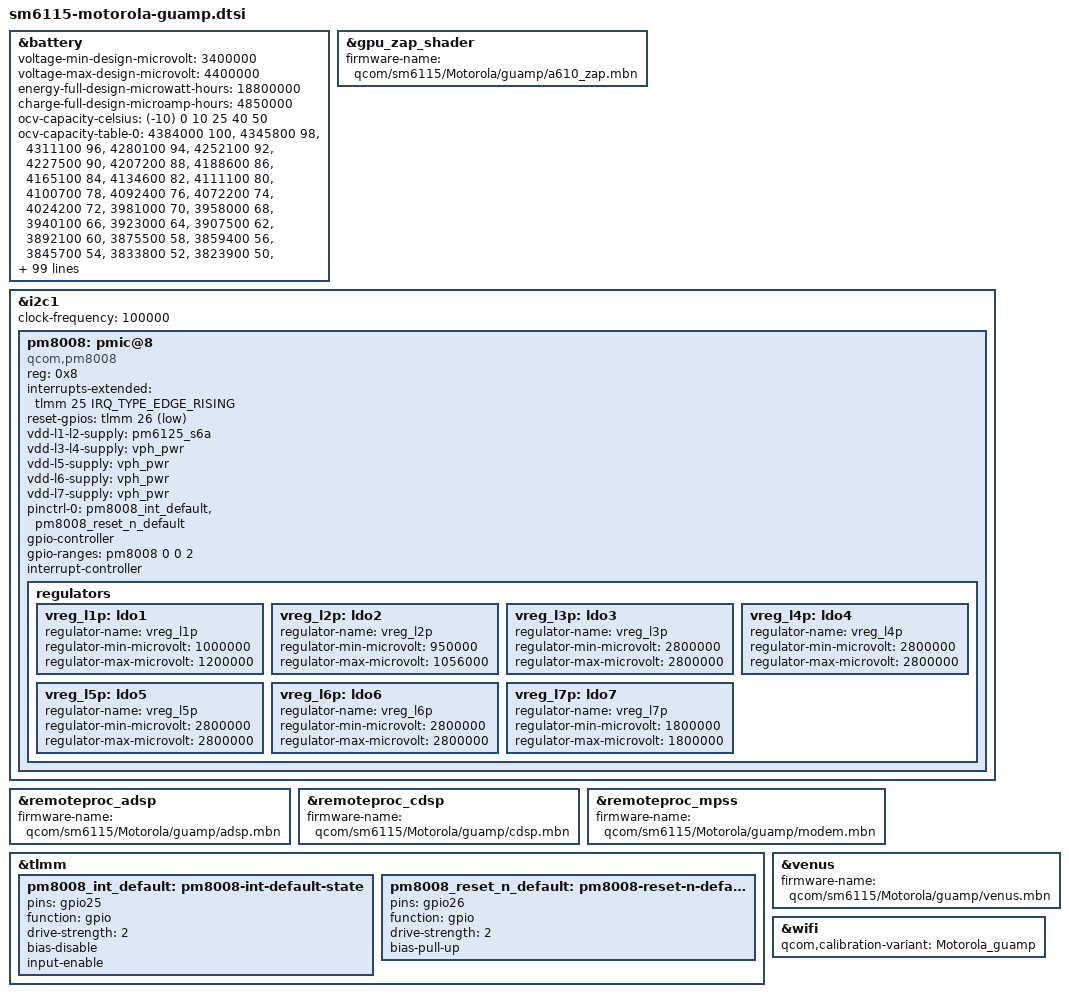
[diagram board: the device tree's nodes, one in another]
// SPDX-License-Identifier: (GPL-2.0+ OR BSD-3-Clause)
/*
 * Copyright (c) 2026, Val Packett <val@packett.cool>
 */

#include "sm6115.dtsi"
#include "sm6115-motorola-common.dtsi"

&battery {
	voltage-min-design-microvolt = <3400000>;
	voltage-max-design-microvolt = <4400000>;
	energy-full-design-microwatt-hours = <18800000>;
	charge-full-design-microamp-hours = <4850000>;

	ocv-capacity-celsius = <(-10) 0 10 25 40 50>;

	ocv-capacity-table-0 =
		<4384000 100>, <4345800 98>, <4311100 96>, <4280100 94>,
		<4252100 92>, <4227500 90>, <4207200 88>, <4188600 86>,
		<4165100 84>, <4134600 82>, <4111100 80>, <4100700 78>,
		<4092400 76>, <4072200 74>, <4024200 72>, <3981000 70>,
		<3958000 68>, <3940100 66>, <3923000 64>, <3907500 62>,
		<3892100 60>, <3875500 58>, <3859400 56>, <3845700 54>,
		<3833800 52>, <3823900 50>, <3816000 48>, <3809300 46>,
		<3803000 44>, <3797100 42>, <3791500 40>, <3786000 38>,
		<3780800 36>, <3775100 34>, <3769400 32>, <3763400 30>,
		<3757100 28>, <3750600 26>, <3744100 24>, <3737600 22>,
		<3731100 20>, <3724800 18>, <3718300 16>, <3711600 14>,
		<3703900 12>, <3693500 10>, <3688000 9>, <3680900 8>,
		<3672100 7>, <3657600 6>, <3633000 5>, <3592200 4>,
		<3532000 3>, <3443800 2>, <3305600 1>;

	ocv-capacity-table-1 =
		<4382000 100>, <4347400 98>, <4315800 96>, <4287600 94>,
		<4262600 92>, <4238400 90>, <4214200 88>, <4190500 86>,
		<4166800 84>, <4142900 82>, <4120900 80>, <4102900 78>,
		<4085800 76>, <4064800 74>, <4039300 72>, <4012900 70>,
		<3985900 68>, <3959900 66>, <3939900 64>, <3924200 62>,
		<3909200 60>, <3893000 58>, <3877200 56>, <3862900 54>,
		<3850200 52>, <3837800 50>, <3824400 48>, <3812000 46>,
		<3803700 44>, <3797800 42>, <3792900 40>, <3789000 38>,
		<3785400 36>, <3781200 34>, <3776500 32>, <3771500 30>,
		<3766800 28>, <3761800 26>, <3755600 24>, <3748300 22>,
		<3740000 20>, <3730300 18>, <3719300 16>, <3707500 14>,
		<3697100 12>, <3687900 10>, <3683900 9>, <3679500 8>,
		<3673600 7>, <3664100 6>, <3643300 5>, <3601900 4>,
		<3541600 3>, <3455500 2>, <3320700 1>;

	ocv-capacity-table-2 =
		<4381000 100>, <4351700 98>, <4323800 96>, <4297400 94>,
		<4272400 92>, <4248100 90>, <4224100 88>, <4200600 86>,
		<4177800 84>, <4155600 82>, <4134000 80>, <4113300 78>,
		<4093000 76>, <4072300 74>, <4051300 72>, <4029700 70>,
		<4006300 68>, <3982700 66>, <3961100 64>, <3940800 62>,
		<3921900 60>, <3903600 58>, <3886900 56>, <3872000 54>,
		<3858800 52>, <3846700 50>, <3835800 48>, <3825700 46>,
		<3816500 44>, <3807900 42>, <3800100 40>, <3792600 38>,
		<3786000 36>, <3781000 34>, <3777100 32>, <3773100 30>,
		<3769300 28>, <3765100 26>, <3759600 24>, <3752800 22>,
		<3744800 20>, <3735000 18>, <3723400 16>, <3709000 14>,
		<3696800 12>, <3688900 10>, <3686300 9>, <3684000 8>,
		<3679900 7>, <3671800 6>, <3647900 5>, <3599800 4>,
		<3535000 3>, <3447700 2>, <3319500 1>;

	ocv-capacity-table-3 =
		<4374500 100>, <4344200 98>, <4315800 96>, <4289700 94>,
		<4265800 92>, <4242300 90>, <4218800 88>, <4195500 86>,
		<4172600 84>, <4150000 82>, <4128000 80>, <4106800 78>,
		<4086100 76>, <4065600 74>, <4044900 72>, <4024900 70>,
		<4005700 68>, <3987300 66>, <3970300 64>, <3955200 62>,
		<3938400 60>, <3915500 58>, <3891200 56>, <3873300 54>,
		<3859400 52>, <3847400 50>, <3836700 48>, <3827300 46>,
		<3818500 44>, <3810400 42>, <3803100 40>, <3796300 38>,
		<3790200 36>, <3784300 34>, <3779000 32>, <3773600 30>,
		<3767800 28>, <3761700 26>, <3755000 24>, <3747800 22>,
		<3739700 20>, <3730000 18>, <3718700 16>, <3704800 14>,
		<3693100 12>, <3687700 10>, <3686000 9>, <3684000 8>,
		<3681100 7>, <3674000 6>, <3648000 5>, <3600400 4>,
		<3537900 3>, <3454700 2>, <3329300 1>;

	ocv-capacity-table-4 =
		<4372500 100>, <4344800 98>, <4318300 96>, <4293100 94>,
		<4269200 92>, <4245700 90>, <4222200 88>, <4199000 86>,
		<4176100 84>, <4153400 82>, <4131100 80>, <4109100 78>,
		<4087600 76>, <4067100 74>, <4047200 72>, <4027900 70>,
		<4009000 68>, <3990900 66>, <3974200 64>, <3959000 62>,
		<3941900 60>, <3919100 58>, <3895300 56>, <3877300 54>,
		<3862400 52>, <3849700 50>, <3838800 48>, <3829200 46>,
		<3820400 44>, <3812500 42>, <3805300 40>, <3798800 38>,
		<3792700 36>, <3786200 34>, <3779500 32>, <3772000 30>,
		<3763300 28>, <3754300 26>, <3746200 24>, <3738700 22>,
		<3730700 20>, <3721600 18>, <3710900 16>, <3697100 14>,
		<3686400 12>, <3682000 10>, <3680600 9>, <3679300 8>,
		<3676600 7>, <3667800 6>, <3637400 5>, <3588100 4>,
		<3523900 3>, <3435900 2>, <3308000 1>;

	ocv-capacity-table-5 =
		<4371500 100>, <4344300 98>, <4318200 96>, <4293400 94>,
		<4269700 92>, <4246400 90>, <4222900 88>, <4199600 86>,
		<4176600 84>, <4153900 82>, <4131600 80>, <4109800 78>,
		<4088300 76>, <4067700 74>, <4047400 72>, <4028100 70>,
		<4009600 68>, <3991900 66>, <3975200 64>, <3959600 62>,
		<3942200 60>, <3919500 58>, <3896000 56>, <3878100 54>,
		<3863200 52>, <3850400 50>, <3839300 48>, <3829500 46>,
		<3820500 44>, <3812400 42>, <3805100 40>, <3798300 38>,
		<3791900 36>, <3785100 34>, <3778000 32>, <3769800 30>,
		<3759500 28>, <3748700 26>, <3740000 24>, <3732400 22>,
		<3724300 20>, <3715400 18>, <3704800 16>, <3690800 14>,
		<3680400 12>, <3676300 10>, <3675300 9>, <3674100 8>,
		<3670900 7>, <3660200 6>, <3627200 5>, <3577200 4>,
		<3512300 3>, <3423400 2>, <3292200 1>;
};

&gpu_zap_shader {
	firmware-name = "qcom/sm6115/Motorola/guamp/a610_zap.mbn";
};

&i2c1 {
	clock-frequency = <100000>;
	status = "okay";

	pm8008: pmic@8 {
		compatible = "qcom,pm8008";
		reg = <0x8>;

		interrupts-extended = <&tlmm 25 IRQ_TYPE_EDGE_RISING>;
		reset-gpios = <&tlmm 26 GPIO_ACTIVE_LOW>;

		vdd-l1-l2-supply = <&pm6125_s6a>;
		vdd-l3-l4-supply = <&vph_pwr>;
		vdd-l5-supply = <&vph_pwr>;
		vdd-l6-supply = <&vph_pwr>;
		vdd-l7-supply = <&vph_pwr>;

		pinctrl-0 = <&pm8008_int_default>, <&pm8008_reset_n_default>;
		pinctrl-names = "default";

		gpio-controller;
		#gpio-cells = <2>;
		gpio-ranges = <&pm8008 0 0 2>;

		interrupt-controller;
		#interrupt-cells = <2>;

		#thermal-sensor-cells = <0>;

		regulators {
			vreg_l1p: ldo1 {
				regulator-name = "vreg_l1p";
				regulator-min-microvolt = <1000000>;
				regulator-max-microvolt = <1200000>;
			};

			vreg_l2p: ldo2 {
				regulator-name = "vreg_l2p";
				regulator-min-microvolt = <950000>;
				regulator-max-microvolt = <1056000>;
			};

			vreg_l3p: ldo3 {
				regulator-name = "vreg_l3p";
				regulator-min-microvolt = <2800000>;
				regulator-max-microvolt = <2800000>;
			};

			vreg_l4p: ldo4 {
				regulator-name = "vreg_l4p";
				regulator-min-microvolt = <2800000>;
				regulator-max-microvolt = <2800000>;
			};

			vreg_l5p: ldo5 {
				regulator-name = "vreg_l5p";
				regulator-min-microvolt = <2800000>;
				regulator-max-microvolt = <2800000>;
			};

			vreg_l6p: ldo6 {
				regulator-name = "vreg_l6p";
				regulator-min-microvolt = <2800000>;
				regulator-max-microvolt = <2800000>;
			};

			vreg_l7p: ldo7 {
				regulator-name = "vreg_l7p";
				regulator-min-microvolt = <1800000>;
				regulator-max-microvolt = <1800000>;
			};
		};
	};
};

&remoteproc_adsp {
	firmware-name = "qcom/sm6115/Motorola/guamp/adsp.mbn";
	status = "okay";
};

&remoteproc_cdsp {
	firmware-name = "qcom/sm6115/Motorola/guamp/cdsp.mbn";
	status = "okay";
};

&remoteproc_mpss {
	firmware-name = "qcom/sm6115/Motorola/guamp/modem.mbn";
	status = "okay";
};

&tlmm {
	pm8008_int_default: pm8008-int-default-state {
		pins = "gpio25";
		function = "gpio";
		drive-strength = <2>;
		bias-disable;
		input-enable;
	};

	pm8008_reset_n_default: pm8008-reset-n-default-state {
		pins = "gpio26";
		function = "gpio";
		drive-strength = <2>;
		bias-pull-up;
	};
};

&venus {
	firmware-name = "qcom/sm6115/Motorola/guamp/venus.mbn";
	status = "okay";
};

&wifi {
	qcom,calibration-variant = "Motorola_guamp";
};
